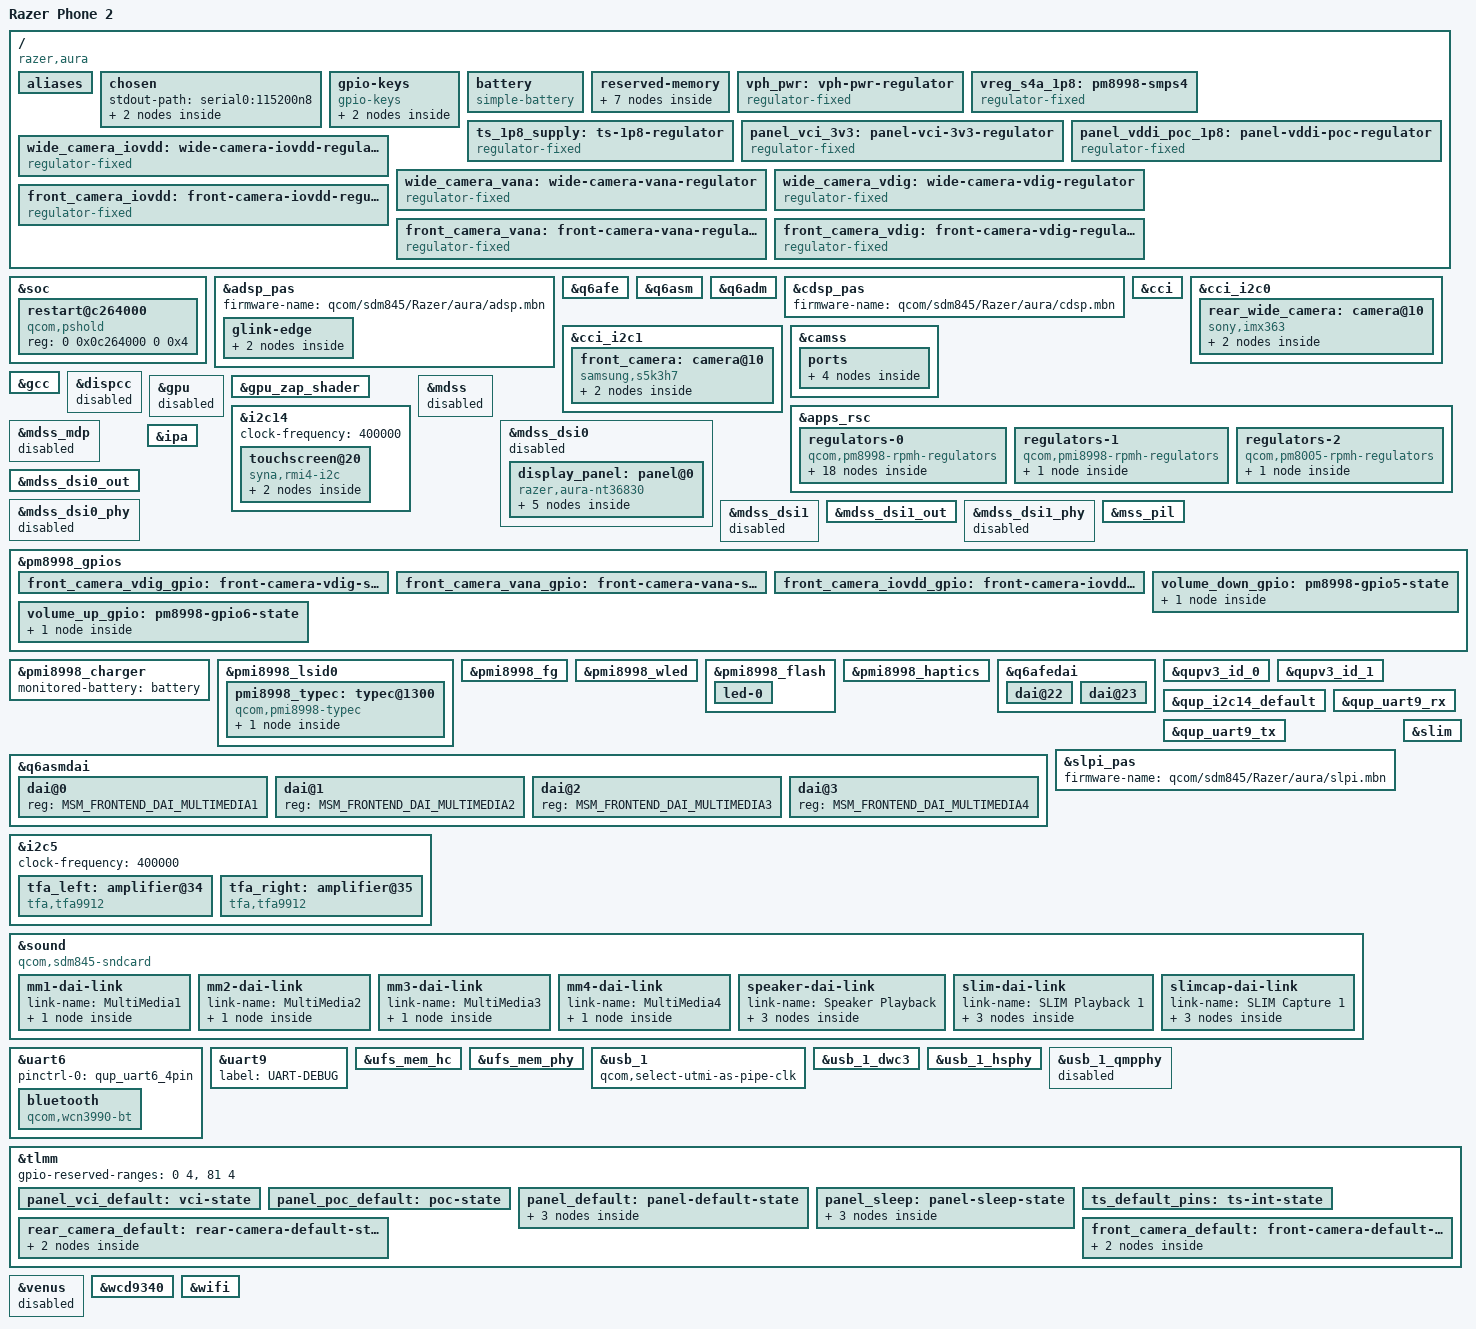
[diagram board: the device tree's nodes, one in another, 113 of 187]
// SPDX-License-Identifier: GPL-2.0
/*
 * SDM845 Razer Phone 2 (aura) device tree source.
 *
 * Copyright (c) 2024 Linux Community
 *
 * Based on sdm845-oneplus-common.dtsi / sdm845-oneplus-fajita.dts
 * and information extracted from Razer Phone 2 Android kernel sources.
 *
 * Hardware:
 *   SoC:     Qualcomm SDM845 (Snapdragon 845)
 *   Display: NovaTeK NT36830 5.72" 1440x2560 120Hz AMOLED (Dual DSI + DSC)
 *   Touch:   Synaptics RMI4 DSX on I2C-14 @ 0x20
 *   WiFi:    Qualcomm WCN3990 (ath10k_snoc)
 *   PMIC:    PM8998 (primary) + PMI8998 (secondary)
 *   USB:     DWC3 (a600000.dwc3) USB 3.1 Type-C
 *   Audio:   WCD9340 (tavil) via Slimbus
 *   Storage: UFS 2.1 (1d84000.ufshc)
 */

/dts-v1/;

#include <dt-bindings/arm/qcom,ids.h>
#include <dt-bindings/gpio/gpio.h>
#include <dt-bindings/input/input.h>
#include <dt-bindings/input/linux-event-codes.h>
#include <dt-bindings/input/qcom,spmi-haptics.h>
#include <dt-bindings/leds/common.h>
#include <dt-bindings/phy/phy-qcom-qusb2.h>
#include <dt-bindings/pinctrl/qcom,pmic-gpio.h>
#include <dt-bindings/regulator/qcom,rpmh-regulator.h>
#include <dt-bindings/sound/qcom,q6afe.h>
#include <dt-bindings/sound/qcom,q6asm.h>
#include <dt-bindings/usb/pd.h>

#include "sdm845.dtsi"
#include "sdm845-wcd9340.dtsi"
#include "pm8998.dtsi"
#include "pmi8998.dtsi"

/delete-node/ &rmtfs_mem;

/ {
	model = "Razer Phone 2";
	compatible = "razer,aura", "qcom,sdm845";
	chassis-type = "handset";

	/*
	 * Match the factory Android boot DTB. Keep this revision aligned while
	 * validating TZ-authenticated MSS firmware loading.
	 */
	qcom,msm-id = <QCOM_ID_SDM845 0x20000>;
	qcom,board-id = <0 0>;

	aliases {
		serial0 = &uart9;
		serial1 = &uart6;
	};

	chosen {
		#address-cells = <2>;
		#size-cells = <2>;
		ranges;

		stdout-path = "serial0:115200n8";

		/*
		 * Keep the bootloader framebuffer alive for the debug-safe display path.
		 * This mirrors the previously successful PMOS-style bring-up direction:
		 * preserve simpledrm first, and defer full NT36830 takeover until the
		 * rest of the boot chain is observable and stable.
		 */
		framebuffer: framebuffer@9d400000 {
			compatible = "simple-framebuffer";
			reg = <0 0x9d400000 0 0x00f00000>;
			width = <1440>;
			height = <2560>;
			stride = <(1440 * 4)>;
			format = "a8r8g8b8";

			/*
			 * Fake panel node for simpledrm DPI calculation and saner probe
			 * ordering, following the conservative SDM845 phone bring-up pattern.
			 * 2026-07-06: this was dropped when the 7.1 DTS was adopted from
			 * codex/linux-7.1-display, which is why 7.1 had no /dev/fb0 or
			 * /dev/dri at all (simpledrm never created a device) even though
			 * the same physical bootloader framebuffer worked fine on 6.16.
			 */
			panel = <&fb_panel>;

			fb_panel: fb-panel {
				width-mm = <71>;
				height-mm = <126>;
			};
		};
	};

	gpio-keys {
		compatible = "gpio-keys";
		label = "Volume keys";
		autorepeat;

		pinctrl-names = "default";
		pinctrl-0 = <&volume_down_gpio &volume_up_gpio>;

		key-vol-down {
			label = "Volume down";
			linux,code = <KEY_VOLUMEDOWN>;
			gpios = <&pm8998_gpios 5 GPIO_ACTIVE_LOW>;
			debounce-interval = <15>;
		};

		key-vol-up {
			label = "Volume up";
			linux,code = <KEY_VOLUMEUP>;
			gpios = <&pm8998_gpios 6 GPIO_ACTIVE_LOW>;
			debounce-interval = <15>;
		};
	};

	battery: battery {
		compatible = "simple-battery";

		charge-full-design-microamp-hours = <4000000>;
		voltage-min-design-microvolt = <3400000>;
		/* Factory battery profile: 4.4 V, 4000 mAh. */
		voltage-max-design-microvolt = <4400000>;
		/*
		 * Keep mainline USB DCP charging conservative.  The factory
		 * downstream tree allows up to 3.9 A, but that policy also
		 * depends on downstream JEITA and step-charging support.
		 */
		constant-charge-current-max-microamp = <2000000>;
	};

	reserved-memory {
		/*
		 * Bootloader-painted splash/continuous-splash framebuffer.
		 * 2026-07-07: this region was never marked no-map, so it stayed
		 * part of generic System RAM (confirmed via /proc/iomem:
		 * 97c00000-aeffffff : System RAM covers it). Newer simpledrm
		 * added a strict devm_request_mem_region() acquire in its probe
		 * path, which then fails with -ENOMEM ("could not acquire memory
		 * region") because normal System RAM is already claimed by the
		 * kernel's own memory management. The older simpledrm on 6.16
		 * tolerated the missing reservation; 7.1 does not. Must exactly
		 * match the /chosen/framebuffer@9d400000 reg below.
		 */
		cont_splash_mem: framebuffer-mem@9d400000 {
			reg = <0 0x9d400000 0 0x00f00000>;
			no-map;
		};

		/*
		 * Razer and OnePlus Android downstream DTBs describe rmtfs as a
		 * dynamically allocated 2 MiB sharedmem-uio region with guard memory.
		 * Follow the proven OnePlus mainline pattern for this contrast test:
		 * keep the old SDM845 rmtfs/modem window reserved below, and expose
		 * the active rmtfs region at the high address used by OnePlus.
		 */
		rmtfs_mem: rmtfs-mem@f5b00000 {
			compatible = "qcom,rmtfs-mem";
			reg = <0 0xf5b00000 0 0x202000>;
			no-map;

			qcom,client-id = <1>;
			qcom,vmid = <QCOM_SCM_VMID_MSS_MSA>;
			qcom,use-guard-pages;
		};

		/*
		 * Match the OnePlus/Samsung SDM845 mainline safety reserve for the old
		 * downstream modem/rmtfs window. This keeps Linux from allocating the
		 * area while rmtfs itself is served from the high active region above.
		 */
		removed_region: removed-region@88f00000 {
			no-map;
			reg = <0 0x88f00000 0 0x1c00000>;
		};

		/*
		 * Ramoops region for persistent kernel crash logs.
		 * Survives warm reboots for post-mortem debugging.
		 */
		ramoops: ramoops@ac300000 {
			compatible = "ramoops";
			reg = <0 0xac300000 0 0x400000>;
			record-size = <0x40000>;
			console-size = <0x40000>;
			ftrace-size = <0x40000>;
			pmsg-size = <0x200000>;
			ecc-size = <16>;
		};

		/*
		 * FIH/Razer downstream reserves these OEM regions. They are not
		 * directly consumed by mainline drivers yet, but they should not
		 * be handed to Linux while validating modem firmware stability.
		 */
		fih_nv_mem: fih-nv@af000000 {
			compatible = "removed-dma-pool";
			no-map;
			reg = <0 0xaf000000 0 0x800000>;
		};

		fih_pstore_mem: fih-pstore@af800000 {
			compatible = "removed-dma-pool";
			no-map;
			reg = <0 0xaf800000 0 0x200000>;
		};

		fih_mem: fih@afa00000 {
			compatible = "removed-dma-pool";
			no-map;
			reg = <0 0xafa00000 0 0x600000>;
		};
	};

	/*
	 * Main battery/bus power rail. On Razer Phone 2, this is supplied
	 * by the 4.2V battery through a protection board.
	 */
	vph_pwr: vph-pwr-regulator {
		compatible = "regulator-fixed";
		regulator-name = "vph_pwr";
		regulator-min-microvolt = <3700000>;
		regulator-max-microvolt = <3700000>;
	};

	/*
	 * PM8998 SMPS4 is always-on and not managed by RPMh.
	 * Model as fixed 1.8V regulator.
	 */
	vreg_s4a_1p8: pm8998-smps4 {
		compatible = "regulator-fixed";
		regulator-name = "vreg_s4a_1p8";

		regulator-min-microvolt = <1800000>;
		regulator-max-microvolt = <1800000>;

		regulator-always-on;
		regulator-boot-on;

		vin-supply = <&vph_pwr>;
	};

	/*
	 * Touchscreen 1.8V I/O supply, controlled via GPIO.
	 * Modeled as fixed regulator since we don't have schematics.
	 */
	ts_1p8_supply: ts-1p8-regulator {
		compatible = "regulator-fixed";
		regulator-name = "ts_1p8_supply";

		regulator-min-microvolt = <1800000>;
		regulator-max-microvolt = <1800000>;

		gpio = <&tlmm 88 GPIO_ACTIVE_HIGH>;
		enable-active-high;
	};

	/*
	 * Display panel VCI 3.3V supply.
	 * Controlled via TLMM GPIO, active high.
	 */
	panel_vci_3v3: panel-vci-3v3-regulator {
		compatible = "regulator-fixed";
		regulator-name = "LCD_VCI_3V";

		regulator-min-microvolt = <3300000>;
		regulator-max-microvolt = <3300000>;

		gpio = <&tlmm 26 GPIO_ACTIVE_HIGH>;
		enable-active-high;
		pinctrl-0 = <&panel_vci_default>;
		pinctrl-names = "default";
		regulator-boot-on;
		regulator-always-on;
	};

	/*
	 * Display panel VDDI / POC 1.8V supply.
	 * Controlled via TLMM GPIO, active high.
	 */
	panel_vddi_poc_1p8: panel-vddi-poc-regulator {
		compatible = "regulator-fixed";
		regulator-name = "VDDI_POC";

		regulator-min-microvolt = <1800000>;
		regulator-max-microvolt = <1800000>;

		gpio = <&tlmm 25 GPIO_ACTIVE_HIGH>;
		enable-active-high;
		pinctrl-0 = <&panel_poc_default>;
		pinctrl-names = "default";
		regulator-boot-on;
		regulator-always-on;
	};

	/* Rear wide-camera I/O rail from the factory RC2 camera topology. */
	wide_camera_iovdd: wide-camera-iovdd-regulator {
		compatible = "regulator-fixed";
		regulator-name = "wide_camera_iovdd";
		regulator-min-microvolt = <1800000>;
		regulator-max-microvolt = <1800000>;
		regulator-enable-ramp-delay = <233>;
		vin-supply = <&vreg_lvs1a_1p8>;
		gpio = <&pm8998_gpios 11 GPIO_ACTIVE_HIGH>;
		enable-active-high;
	};

	wide_camera_vana: wide-camera-vana-regulator {
		compatible = "regulator-fixed";
		regulator-name = "wide_camera_vana";
		regulator-min-microvolt = <3312000>;
		regulator-max-microvolt = <3312000>;
		vin-supply = <&vreg_bob>;
		gpio = <&pm8998_gpios 12 GPIO_ACTIVE_HIGH>;
		enable-active-high;
	};

	wide_camera_vdig: wide-camera-vdig-regulator {
		compatible = "regulator-fixed";
		regulator-name = "wide_camera_vdig";
		regulator-min-microvolt = <1352000>;
		regulator-max-microvolt = <1352000>;
		vin-supply = <&vreg_s3a_1p35>;
		gpio = <&pm8998_gpios 10 GPIO_ACTIVE_HIGH>;
		enable-active-high;
	};

	/* Chicony S5K3H7 front-camera rails from the factory RC2 topology. */
	front_camera_iovdd: front-camera-iovdd-regulator {
		compatible = "regulator-fixed";
		regulator-name = "front_camera_iovdd";
		regulator-min-microvolt = <1800000>;
		regulator-max-microvolt = <1800000>;
		regulator-enable-ramp-delay = <233>;
		vin-supply = <&vreg_lvs1a_1p8>;
		gpio = <&pm8998_gpios 8 GPIO_ACTIVE_HIGH>;
		pinctrl-names = "default";
		pinctrl-0 = <&front_camera_iovdd_gpio>;
		enable-active-high;
	};

	front_camera_vana: front-camera-vana-regulator {
		compatible = "regulator-fixed";
		regulator-name = "front_camera_vana";
		regulator-min-microvolt = <2800000>;
		regulator-max-microvolt = <2800000>;
		gpio = <&pm8998_gpios 7 GPIO_ACTIVE_HIGH>;
		pinctrl-names = "default";
		pinctrl-0 = <&front_camera_vana_gpio>;
		enable-active-high;
	};

	front_camera_vdig: front-camera-vdig-regulator {
		compatible = "regulator-fixed";
		regulator-name = "front_camera_vdig";
		regulator-min-microvolt = <1050000>;
		regulator-max-microvolt = <1050000>;
		gpio = <&pm8998_gpios 4 GPIO_ACTIVE_HIGH>;
		pinctrl-names = "default";
		pinctrl-0 = <&front_camera_vdig_gpio>;
		enable-active-high;
	};
};

/*
 * Razer's downstream SDM845 poweroff path drops PS_HOLD at 0x0c264000
 * after programming PM8998 PON for shutdown. PSCI SYSTEM_OFF returns on
 * this firmware, so expose the register to the mainline msm-poweroff driver.
 */
&soc {
	restart@c264000 {
		compatible = "qcom,pshold";
		reg = <0 0x0c264000 0 0x4>;
	};
};

/*
 * ==========================================================================
 * Subsystem Firmware Paths
 * ==========================================================================
 * Firmware blobs extracted from Razer Phone 2 stock ROM.
 * Place in /usr/lib/firmware/qcom/sdm845/Razer/aura/
 */

&adsp_pas {
	firmware-name = "qcom/sdm845/Razer/aura/adsp.mbn";
	/*
	 * WiFi/MSS controlled test: factory Android keeps ADSP/SLPI/CDSP
	 * available. Keep audio/SLIM users disabled, but allow the remoteproc
	 * domain to boot so modem root_pd can resolve early dependencies.
	 */
	status = "okay";

	/*
	 * Razer's stock ADSP image exposes APR over GLINK, but its service
	 * registry does not publish msm/adsp/audio_pd. Register the audio APR
	 * children as soon as the edge appears instead of waiting forever for a
	 * protection-domain notification that this firmware cannot send.
	 */
	glink-edge {
		apr {
			service@3 {
				/delete-property/ qcom,protection-domain;
			};
		};
	};
};

&q6afe {
	/delete-property/ qcom,protection-domain;
};

&q6asm {
	/delete-property/ qcom,protection-domain;
};

&q6adm {
	/delete-property/ qcom,protection-domain;
};

&cdsp_pas {
	firmware-name = "qcom/sdm845/Razer/aura/cdsp.mbn";
	status = "okay";
};

/*
 * Factory rear-wide topology: Lite-On IMX363, CCI0, CSIPHY0, MCLK0 on
 * GPIO13, reset on GPIO80. Autofocus and OIS are not needed for preview.
 */
&cci {
	status = "okay";
};

&cci_i2c0 {
	status = "okay";

	rear_wide_camera: camera@10 {
		compatible = "sony,imx363";
		reg = <0x10>;
		clocks = <&clock_camcc CAM_CC_MCLK0_CLK>;
		assigned-clocks = <&clock_camcc CAM_CC_MCLK0_CLK>;
		assigned-clock-rates = <24000000>;
		clock-frequency = <24000000>;
		pinctrl-names = "default";
		pinctrl-0 = <&rear_camera_default>;
		reset-gpios = <&tlmm 80 GPIO_ACTIVE_LOW>;
		vif-supply = <&wide_camera_iovdd>;
		vana-supply = <&wide_camera_vana>;
		vdig-supply = <&wide_camera_vdig>;
		orientation = <1>;
		rotation = <90>;

		port {
			rear_imx363_ep: endpoint {
				bus-type = <4>;
				clock-lanes = <1>;
				data-lanes = <1 2 3 4>;
				link-frequencies = /bits/ 64 <636000000 321000000>;
				remote-endpoint = <&camss_csiphy0_ep>;
			};
		};
	};
};

&cci_i2c1 {
	status = "okay";

	front_camera: camera@10 {
		compatible = "samsung,s5k3h7";
		reg = <0x10>;
		clocks = <&clock_camcc CAM_CC_MCLK2_CLK>;
		assigned-clocks = <&clock_camcc CAM_CC_MCLK2_CLK>;
		assigned-clock-rates = <24000000>;
		clock-frequency = <24000000>;
		pinctrl-names = "default";
		pinctrl-0 = <&front_camera_default>;
		reset-gpios = <&tlmm 9 GPIO_ACTIVE_LOW>;
		vdda-supply = <&front_camera_vana>;
		vddd-supply = <&front_camera_vdig>;
		vddio-supply = <&front_camera_iovdd>;
		orientation = <0>;
		rotation = <90>;

		port {
			front_s5k3h7_ep: endpoint {
				bus-type = <4>;
				clock-lanes = <1>;
				data-lanes = <1 2 3 4>;
				link-frequencies = /bits/ 64 <330000000>;
				remote-endpoint = <&camss_csiphy2_ep>;
			};
		};
	};
};

&camss {
	vdda-phy-supply = <&vdda_mipi_dsi0_pll>;
	vdda-pll-supply = <&vdda_mipi_dsi0_1p2>;
	vdda-csi0-supply = <&vdda_mipi_dsi0_pll>;
	vdda-csi1-supply = <&vdda_mipi_dsi0_pll>;
	vdda-csi2-supply = <&vdda_mipi_dsi0_pll>;
	status = "okay";

	ports {
		#address-cells = <1>;
		#size-cells = <0>;

		port@0 {
			reg = <0>;
			camss_csiphy0_ep: endpoint {
				bus-type = <4>;
				clock-lanes = <7>;
				data-lanes = <0 1 2 3>;
				remote-endpoint = <&rear_imx363_ep>;
			};
		};

		port@2 {
			reg = <2>;
			camss_csiphy2_ep: endpoint {
				bus-type = <4>;
				clock-lanes = <7>;
				data-lanes = <0 1 2 3>;
				remote-endpoint = <&front_s5k3h7_ep>;
			};
		};
	};
};

/*
 * ==========================================================================
 * RPMh Regulators (PM8998 + PMI8998)
 * ==========================================================================
 * Voltage values derived from Razer Phone 2 Android kernel device tree.
 * PM8998 provides core rail SMPS and peripheral LDO regulators.
 * PMI8998 provides BOB (Battery-on-Board) bypass regulator.
 */
&apps_rsc {
	regulators-0 {
		compatible = "qcom,pm8998-rpmh-regulators";
		qcom,pmic-id = "a";

		vdd-s1-supply = <&vph_pwr>;
		vdd-s2-supply = <&vph_pwr>;
		vdd-s3-supply = <&vph_pwr>;
		vdd-s4-supply = <&vph_pwr>;
		vdd-s5-supply = <&vph_pwr>;
		vdd-s6-supply = <&vph_pwr>;
		vdd-s7-supply = <&vph_pwr>;
		vdd-s8-supply = <&vph_pwr>;
		vdd-s9-supply = <&vph_pwr>;
		vdd-s10-supply = <&vph_pwr>;
		vdd-s11-supply = <&vph_pwr>;
		vdd-s12-supply = <&vph_pwr>;
		vdd-s13-supply = <&vph_pwr>;
		vdd-l1-l27-supply = <&vreg_s7a_1p025>;
		vdd-l2-l8-l17-supply = <&vreg_s3a_1p35>;
		vdd-l3-l11-supply = <&vreg_s7a_1p025>;
		vdd-l4-l5-supply = <&vreg_s7a_1p025>;
		vdd-l6-supply = <&vph_pwr>;
		vdd-l7-l12-l14-l15-supply = <&vreg_s5a_2p04>;
		vdd-l9-supply = <&vreg_bob>;
		vdd-l10-l23-l25-supply = <&vreg_bob>;
		vdd-l13-l19-l21-supply = <&vreg_bob>;
		vdd-l16-l28-supply = <&vreg_bob>;
		vdd-l18-l22-supply = <&vreg_bob>;
		vdd-l20-l24-supply = <&vreg_bob>;
		vdd-l26-supply = <&vreg_s3a_1p35>;
		vin-lvs-1-2-supply = <&vreg_s4a_1p8>;

		/* SMPS3: CX/MX related, 1.352V */
		vreg_s3a_1p35: smps3 {
			regulator-min-microvolt = <1352000>;
			regulator-max-microvolt = <1352000>;
		};

		/* SMPS5: I/O rail, 2.04V */
		vreg_s5a_2p04: smps5 {
			regulator-min-microvolt = <1904000>;
			regulator-max-microvolt = <2040000>;
		};

		/* SMPS7: Core logic, 1.025V */
		vreg_s7a_1p025: smps7 {
			regulator-min-microvolt = <900000>;
			regulator-max-microvolt = <1028000>;
		};

		/* LDO1: USB SS PHY core + DSI PLL analog, 0.88V (nldo) */
		vdda_usb1_ss_core:
		vdda_mipi_dsi0_pll: ldo1 {
			regulator-min-microvolt = <880000>;
			regulator-max-microvolt = <880000>;
			regulator-initial-mode = <RPMH_REGULATOR_MODE_HPM>;
		};

		/* LDO2: DDR/SRAM, 1.2V (always-on) */
		vreg_l2a_1p2: ldo2 {
			regulator-min-microvolt = <1200000>;
			regulator-max-microvolt = <1200000>;
			regulator-initial-mode = <RPMH_REGULATOR_MODE_HPM>;
			regulator-always-on;
		};

		/* LDO5: WCSS CX/MX supply for WiFi/BT, 0.8V */
		vreg_l5a_0p8: ldo5 {
			regulator-min-microvolt = <800000>;
			regulator-max-microvolt = <800000>;
			regulator-initial-mode = <RPMH_REGULATOR_MODE_HPM>;
		};

		/* LDO7: WiFi/BT XO, UFS core, 1.8V */
		vreg_l7a_1p8: ldo7 {
			regulator-min-microvolt = <1800000>;
			regulator-max-microvolt = <1800000>;
			regulator-initial-mode = <RPMH_REGULATOR_MODE_HPM>;
		};

		/* LDO10: General purpose 1.8V (pldo, range 1.664-3.704V) */
		vreg_l10a_1p8: ldo10 {
			regulator-min-microvolt = <1704000>;
			regulator-max-microvolt = <2928000>;
			regulator-initial-mode = <RPMH_REGULATOR_MODE_HPM>;
		};

		/* LDO12: QUSB2 HS PHY, 1.8V */
		vdda_qusb_hs0_1p8: ldo12 {
			regulator-min-microvolt = <1800000>;
			regulator-max-microvolt = <1800000>;
			regulator-initial-mode = <RPMH_REGULATOR_MODE_HPM>;
		};

		/* LDO14: DSI panel VDDIO, 1.88V (boot-on for splash screen) */
		vreg_l14a_1p88: ldo14 {
			regulator-min-microvolt = <1800000>;
			regulator-max-microvolt = <1800000>;
			regulator-initial-mode = <RPMH_REGULATOR_MODE_HPM>;
			regulator-boot-on;
			regulator-always-on;
		};

		/* LDO17: WiFi/BT RFA, 1.3V */
		vreg_l17a_1p3: ldo17 {
			regulator-min-microvolt = <1304000>;
			regulator-max-microvolt = <1304000>;
			regulator-initial-mode = <RPMH_REGULATOR_MODE_HPM>;
		};

		/* LDO20: UFS VCC, 2.95V */
		vreg_l20a_2p95: ldo20 {
			regulator-min-microvolt = <2704000>;
			regulator-max-microvolt = <2960000>;
			regulator-initial-mode = <RPMH_REGULATOR_MODE_HPM>;
		};

		/* LDO23: WiFi/BT CH1, 3.3V */
		vreg_l23a_3p3: ldo23 {
			regulator-min-microvolt = <3300000>;
			regulator-max-microvolt = <3312000>;
			regulator-initial-mode = <RPMH_REGULATOR_MODE_HPM>;
		};

		/* LDO24: QUSB2 HS PHY DPDM, 3.088V */
		vdda_qusb_hs0_3p1: ldo24 {
			regulator-min-microvolt = <3088000>;
			regulator-max-microvolt = <3088000>;
			regulator-initial-mode = <RPMH_REGULATOR_MODE_HPM>;
		};

		/* LDO25: WiFi/BT CH0, 3.3V */
		vreg_l25a_3p3: ldo25 {
			regulator-min-microvolt = <3300000>;
			regulator-max-microvolt = <3312000>;
			regulator-initial-mode = <RPMH_REGULATOR_MODE_HPM>;
		};

		/* LDO26: DSI PHY PLL, UFS PHY & USB SS PHY, 1.2V */
		vdda_usb1_ss_1p2:
		vdda_mipi_dsi0_1p2: ldo26 {
			regulator-min-microvolt = <1200000>;
			regulator-max-microvolt = <1200000>;
			regulator-initial-mode = <RPMH_REGULATOR_MODE_HPM>;
		};

		/* LDO28: Touch/sensor supply, 3.0V */
		vreg_l28a_3p0: ldo28 {
			regulator-min-microvolt = <2856000>;
			regulator-max-microvolt = <3008000>;
			regulator-initial-mode = <RPMH_REGULATOR_MODE_HPM>;
		};

		/* Factory camera I/O rail: PM8998 LVS1 fed from S4. */
		vreg_lvs1a_1p8: lvs1 {
			regulator-min-microvolt = <1800000>;
			regulator-max-microvolt = <1800000>;
		};
	};

	/* PMI8998 BOB (Battery-on-Board) bypass regulator */
	regulators-1 {
		compatible = "qcom,pmi8998-rpmh-regulators";
		qcom,pmic-id = "b";

		vdd-bob-supply = <&vph_pwr>;

		vreg_bob: bob {
			regulator-min-microvolt = <3312000>;
			regulator-max-microvolt = <3600000>;
			regulator-initial-mode = <RPMH_REGULATOR_MODE_AUTO>;
			regulator-allow-bypass;
		};
	};

	/* PM8005 (tertiary PMIC) SMPS regulators */
	regulators-2 {
		compatible = "qcom,pm8005-rpmh-regulators";
		qcom,pmic-id = "c";

		vdd-s1-supply = <&vph_pwr>;
		vdd-s2-supply = <&vph_pwr>;
		vdd-s3-supply = <&vph_pwr>;
		vdd-s4-supply = <&vph_pwr>;

		/* SMPS3: GFX/GPU supply, 0.6V */
		vreg_s3c_0p6: smps3 {
			regulator-min-microvolt = <600000>;
			regulator-max-microvolt = <600000>;
		};
	};
};

/*
 * ==========================================================================
 * Clock Controller
 * ==========================================================================
 */
&gcc {
	protected-clocks = <GCC_QSPI_CORE_CLK>,
			   <GCC_QSPI_CORE_CLK_SRC>,
			   <GCC_QSPI_CNOC_PERIPH_AHB_CLK>,
			   <GCC_LPASS_Q6_AXI_CLK>,
			   <GCC_LPASS_SWAY_CLK>;
};

/*
 * ==========================================================================
 * Display/GPU clocks
 * ==========================================================================
 *
 * Stage 1 validates Linux 7.1 while preserving the known-good bootloader
 * framebuffer. Keep these clock domains disabled so probing cannot reset the
 * bootloader scanout before the native NT36830 test stage.
 */
&dispcc {
	status = "disabled";
};

&gpu {
	status = "disabled";
};

/*
 * Adreno 630 zap shader: device-signed split image extracted from the
 * phone's Android vendor_a partition (/vendor/firmware/a630_zap.*). The
 * .mdt split format is loaded by the same mdt loader as .mbn. Generic
 * a630_sqe.fw comes from the same partition; a630_gmu.bin from
 * linux-firmware. Same firmware-name pattern as sdm845-oneplus-common.
 */
&gpu_zap_shader {
	firmware-name = "qcom/sdm845/Razer/aura/a630_zap.mdt";
};

/*
 * ==========================================================================
 * Touchscreen (Synaptics RMI4 DSX)
 * ==========================================================================
 * The Razer Phone 2 uses a Synaptics RMI4 touch controller on I2C bus 14
 * (QUP SE 14 @ 0xa98000) at slave address 0x20.
 *
 * GPIO mapping (from Android kernel RC2_common/touch_synaptics_3708.dtsi):
 *   - Interrupt: TLMM GPIO 31 (active low, level)
 *   - Reset:     TLMM GPIO 32
 *   - Power:     TLMM GPIO 44 (1.8V LDO enable)
 *   - Supply:    VDD = LDO28 (3.0V), VIO = ts_1p8_supply
 *
 * Note: GPIO 122 = MAG_INT_N (magnetometer interrupt), NOT touch IRQ.
 */
&i2c14 {
	status = "okay";
	clock-frequency = <400000>;

	touchscreen@20 {
		compatible = "syna,rmi4-i2c";
		reg = <0x20>;
		#address-cells = <1>;
		#size-cells = <0>;
		interrupts-extended = <&tlmm 31 IRQ_TYPE_LEVEL_LOW>;

		pinctrl-names = "default";
		pinctrl-0 = <&ts_default_pins>;

		vdd-supply = <&vreg_l28a_3p0>;
		vio-supply = <&ts_1p8_supply>;

		syna,reset-delay-ms = <200>;
		syna,startup-delay-ms = <200>;

		rmi4-f01@1 {
			reg = <0x01>;
			syna,nosleep-mode = <1>;
		};

		rmi4-f12@12 {
			reg = <0x12>;
			touchscreen-x-mm = <68>;
			touchscreen-y-mm = <120>;
			syna,sensor-type = <1>;
			syna,rezero-wait-ms = <200>;
		};
	};
};

/*
 * ==========================================================================
 * Display Subsystem (MDSS / Dual DSI / NT36830)
 * ==========================================================================
 * The Razer Phone 2 display uses a NovaTeK NT36830 controller driving a
 * 1440x2560 120Hz AMOLED panel via Dual DSI with Display Stream Compression.
 *
 * Dual DSI configuration:
 *   - DSI0: Left half (720x2560)
 *   - DSI1: Right half (720x2560)
 *   - Combined: 1440x2560
 *
 * Native panel power sequence for the later display-driver test:
 *   1. Enable VDDIO (vreg_l14a_1p88 - 1.8V)
 *   2. Enable VCI (panel_vci_3v3 - 3.3V)
 *   3. Enable POC (panel_vddi_poc_1p8 - 1.8V)
 *   4. Release reset GPIO
 *   5. Send DSI initialization commands
 */
&mdss {
	status = "disabled";
};

&mdss_mdp {
	status = "disabled";
};

&mdss_dsi0 {
	status = "disabled";
	/*
	 * 2026-07-07: mainline's own sdm845.dtsi sets no vdda-supply on
	 * EITHER dsi0 or dsi1 -- this property only exists in this board
	 * file, and it was only ever added to mdss_dsi1 below, not here.
	 * The factory board DTS powers both DSI controllers from the same
	 * named 1.2V analog rail symmetrically (dsi_ctrl0/dsi_ctrl1 both
	 * have vdda-1p2-supply = <&pm8998_l26> in sdm845-sde.dtsi). Leaving
	 * DSI0 without this supply left its analog PLL/PHY rail unpowered
	 * by devicetree while DSI1's was properly enabled -- matches the
	 * observed symptom exactly (stripes/signal-integrity issue on DSI0
	 * only, DSI1 clean).
	 */
	vdda-supply = <&vdda_mipi_dsi0_1p2>;

	qcom,dual-dsi-mode;
	qcom,master-dsi;
	qcom,sync-dual-dsi;

	/*
	 * NT36830 panel node on DSI0 (primary interface).
	 * The panel driver will configure both DSI0 and DSI1 via
	 * the dual-DSI mechanism.
	 *
	 * For dual-DSI: The panel node is defined ONLY on DSI0.
	 * port@0 links to DSI0, port@1 links to DSI1.
	 * The panel driver uses of_graph_get_remote_node(dev, 1, -1)
	 * to find the secondary DSI host.
	 */
	display_panel: panel@0 {
		compatible = "razer,aura-nt36830", "novatek,nt36830";
		reg = <0>;
		backlight = <&pmi8998_wled>;

		/* Power supplies */
		vddio-supply = <&vreg_l14a_1p88>;
		vci-supply = <&panel_vci_3v3>;
		poc-supply = <&panel_vddi_poc_1p8>;

		/* Control GPIOs */
		reset-gpios = <&tlmm 6 GPIO_ACTIVE_LOW>;
		te-gpios = <&tlmm 10 GPIO_ACTIVE_HIGH>;
		/*
		 * panel-mode-gpio (GPIO 52) selects dual DSI mode.
		 * Confirmed from Android DTBO entry-05 qcom,panel-mode-gpio=52.
		 * Currently unused by mainline NT36830 driver.
		 */

		/* Pinctrl states */
		pinctrl-0 = <&panel_default>;
		pinctrl-1 = <&panel_sleep>;
		pinctrl-names = "default", "sleep";

		/*
		 * Dual-DSI port connections.
		 * port@0: primary DSI (DSI0) - left half 720x2560
		 * port@1: secondary DSI (DSI1) - right half 720x2560
		 */
		ports {
			#address-cells = <1>;
			#size-cells = <0>;

			port@0 {
				reg = <0>;
				panel_in_dsi0: endpoint {
					remote-endpoint = <&mdss_dsi0_out>;
				};
			};

			port@1 {
				reg = <1>;
				panel_in_dsi1: endpoint {
					remote-endpoint = <&mdss_dsi1_out>;
				};
			};
		};
	};
};

&mdss_dsi0_out {
	remote-endpoint = <&panel_in_dsi0>;
	data-lanes = <0 1 2 3>;
};

&mdss_dsi0_phy {
	status = "disabled";
	/*
	 * 2026-07-07: factory panel DTS
	 * (qcom,mdss_dsi_nt36830_wqhd_dualdsi_extclk_cmd) hand-tunes these two
	 * D-PHY clock-lane timing values for this exact panel+board instead of
	 * using the SoC-generic computed defaults. Requires kernel-patches/
	 * 0002-drm-msm-dsi-honor-factory-clk-post-pre-override.patch --
	 * mainline's dsi_phy_10nm.c has no DT plumbing for these two factory
	 * properties otherwise and would silently ignore them.
	 */
	qcom,mdss-dsi-t-clk-post = <0x0b>;
	qcom,mdss-dsi-t-clk-pre = <0x21>;
};

/*
 * DSI1: Secondary DSI for dual-DSI panel configuration.
 * No panel node here - the panel is only defined on DSI0.
 * DSI1 is linked via port@1 on the panel node.
 */
&mdss_dsi1 {
	status = "disabled";
	vdda-supply = <&vdda_mipi_dsi0_1p2>;

	qcom,dual-dsi-mode;

	/* DSI1 is slave, so use DSI0 clocks */
	assigned-clock-parents = <&mdss_dsi0_phy 0>,
				 <&mdss_dsi0_phy 1>;
};

&mdss_dsi1_out {
	remote-endpoint = <&panel_in_dsi1>;
	data-lanes = <0 1 2 3>;
};

&mdss_dsi1_phy {
	status = "disabled";
	/*
	 * LK ground truth (register capture 2026-07-07): the bootloader
	 * programs t_clk_post/pre = 0x0b/0x21 on BOTH DSI controllers, not
	 * just DSI0. Same mechanism as the dsi0_phy override above
	 * (kernel-patches/0002).
	 */
	qcom,mdss-dsi-t-clk-post = <0x0b>;
	qcom,mdss-dsi-t-clk-pre = <0x21>;
};

/*
 * ==========================================================================
 * IPA (Internet Protocol Accelerator)
 * ==========================================================================
 */
&ipa {
	qcom,gsi-loader = "self";
	memory-region = <&ipa_fw_mem>;
	firmware-name = "qcom/sdm845/Razer/aura/ipa_fws.mbn";
	/*
	 * WiFi/MSS controlled test: IPA disabled did not prevent the MSS fatal,
	 * and ADSP/SLPI/CDSP alone did not create WLFW. Restore IPA with the
	 * factory remoteproc set to test whether modem root_pd expects the full
	 * modem data path present, rather than treating IPA as the trigger.
	 */
	status = "okay";
};

/*
 * ==========================================================================
 * Modem / WiFi Subsystem
 * ==========================================================================
 */
&mss_pil {
	status = "okay";
	firmware-name = "qcom/sdm845/Razer/aura/mba.mbn",
			"qcom/sdm845/Razer/aura/modem.mbn";
	qcom,fih-nv-memory-region = <&fih_nv_mem>;
};

/*
 * ==========================================================================
 * PMIC GPIO Configuration
 * ==========================================================================
 */
&pm8998_gpios {
	front_camera_vdig_gpio: front-camera-vdig-state {
		pins = "gpio4";
		function = "normal";
		output-low;
		qcom,drive-strength = <PMIC_GPIO_STRENGTH_LOW>;
		power-source = <0>;
	};

	front_camera_vana_gpio: front-camera-vana-state {
		pins = "gpio7";
		function = "normal";
		output-low;
		qcom,drive-strength = <PMIC_GPIO_STRENGTH_LOW>;
		power-source = <0>;
	};

	front_camera_iovdd_gpio: front-camera-iovdd-state {
		pins = "gpio8";
		function = "normal";
		output-low;
		qcom,drive-strength = <PMIC_GPIO_STRENGTH_LOW>;
		power-source = <0>;
	};

	volume_down_gpio: pm8998-gpio5-state {
		pinconf {
			pins = "gpio5";
			function = "normal";
			input-enable;
			bias-pull-up;
			qcom,drive-strength = <0>;
		};
	};

	volume_up_gpio: pm8998-gpio6-state {
		pinconf {
			pins = "gpio6";
			function = "normal";
			input-enable;
			bias-pull-up;
			qcom,drive-strength = <0>;
		};
	};
};

/*
 * ==========================================================================
 * PMI8998 Charger and Fuel Gauge
 * ==========================================================================
 * Keep these enabled in the base device tree and build their drivers into
 * the kernel. Charging must not depend on reaching userspace or loading a
 * module from rootfs when the battery is already low.
 */
&pmi8998_charger {
	status = "okay";
	monitored-battery = <&battery>;
};

/*
 * PMI8998 integrates the Type-C state machine in the SMB2 USBIN peripheral
 * and provides a separate SPMI PD PHY at 0x1700.  Keep the first PD bring-up
 * sink-only: the external 5 V source regulator used by factory Android is not
 * modelled yet, and charging does not require source/host mode.
 */
&pmi8998_lsid0 {
	pmi8998_typec: typec@1300 {
		compatible = "qcom,pmi8998-typec";
		reg = <0x1300>, <0x1700>;

		interrupts = <0x2 0x13 0x7 IRQ_TYPE_EDGE_BOTH>,
			     <0x2 0x17 0x0 IRQ_TYPE_EDGE_RISING>,
			     <0x2 0x17 0x1 IRQ_TYPE_EDGE_RISING>,
			     <0x2 0x17 0x2 IRQ_TYPE_EDGE_RISING>,
			     <0x2 0x17 0x3 IRQ_TYPE_EDGE_RISING>,
			     <0x2 0x17 0x4 IRQ_TYPE_EDGE_RISING>,
			     <0x2 0x17 0x5 IRQ_TYPE_EDGE_RISING>,
			     <0x2 0x17 0x6 IRQ_TYPE_EDGE_RISING>;
		interrupt-names = "type-c-change",
				  "sig-tx",
				  "sig-rx",
				  "msg-tx",
				  "msg-rx",
				  "msg-tx-failed",
				  "msg-tx-discarded",
				  "msg-rx-discarded";

		vdd-pdphy-supply = <&vdda_qusb_hs0_3p1>;
		power-supply = <&pmi8998_charger>;
		status = "okay";

		connector {
			compatible = "usb-c-connector";
			power-role = "sink";
			data-role = "device";
			try-power-role = "sink";

			op-sink-microwatt = <13500000>;
			sink-pdos = <PDO_FIXED(5000, 1500, PDO_FIXED_USB_COMM)
				     PDO_FIXED(9000, 1500, PDO_FIXED_USB_COMM)>;
		};
	};
};

&pmi8998_fg {
	status = "okay";
	power-supplies = <&pmi8998_charger>;
	monitored-battery = <&battery>;
};

/*
 * ==========================================================================
 * PMI8998 WLED (White LED / Backlight)
 * ==========================================================================
 */
&pmi8998_wled {
	/* Razer/FIH rc2 factory values translated to the mainline binding. */
	qcom,enabled-strings = <0 1 2 3>;
	qcom,current-limit-microamp = <20000>;
	qcom,current-boost-limit = <970>;
	qcom,ovp-millivolt = <29600>;
	qcom,switching-freq = <1600>;
	qcom,cabc;
	max-brightness = <4095>;
	default-brightness = <2048>;
	status = "okay";
};

/*
 * ==========================================================================
 * PMI8998 Flash LED
 * ==========================================================================
 */
&pmi8998_flash {
	status = "okay";

	led-0 {
		function = LED_FUNCTION_FLASH;
		color = <LED_COLOR_ID_WHITE>;
		led-sources = <1>;
		led-max-microamp = <500000>;
		flash-max-microamp = <1500000>;
		flash-max-timeout-us = <1280000>;
	};
};

/*
 * ==========================================================================
 * PMI8998 LRA Haptics
 * ==========================================================================
 * Razer's downstream PMI8998 node uses direct play, a 1.3 V maximum, the
 * 800 mA current limit and a 6667 us sample period. Mainline's buffer mode
 * exposes the same actuator through the standard EV_FF/FF_RUMBLE interface.
 */
&pmi8998_haptics {
	status = "okay";
	qcom,actuator-type = <HAP_TYPE_LRA>;
	qcom,wave-shape = <HAP_WAVE_SINE>;
	qcom,play-mode = <HAP_PLAY_DIRECT>;
	qcom,vmax-mv = <1300>;
	qcom,current-limit-milliamp = <800>;
	qcom,wave-play-rate-us = <6667>;
	qcom,lra-auto-res-mode = <HAP_AUTO_RES_NONE>;
	qcom,brake-pattern = <0x3 0x3 0x2 0x1>;
};

/*
 * ==========================================================================
 * Audio Subsystem (QQ6/ASM/AFE DAIs)
 * ==========================================================================
 */
&q6afedai {
	dai@22 {
		reg = <QUATERNARY_MI2S_RX>;
		qcom,sd-lines = <0 1>;
	};

	dai@23 {
		reg = <QUATERNARY_MI2S_TX>;
		qcom,sd-lines = <0>;
	};
};

&q6asmdai {
	dai@0 {
		reg = <MSM_FRONTEND_DAI_MULTIMEDIA1>;
	};

	dai@1 {
		reg = <MSM_FRONTEND_DAI_MULTIMEDIA2>;
	};

	dai@2 {
		reg = <MSM_FRONTEND_DAI_MULTIMEDIA3>;
	};

	dai@3 {
		reg = <MSM_FRONTEND_DAI_MULTIMEDIA4>;
	};
};

/*
 * ==========================================================================
 * QUP (Qualcomm Unified Peripheral) Bus Controllers
 * ==========================================================================
 */
&qupv3_id_0 {
	status = "okay";
};

&qupv3_id_1 {
	status = "okay";
};

/*
 * The SMR7 RC2 audio DTS identifies two NXP TFA9912 smart amplifiers on
 * QUPv3 SE5. Their factory container is installed as tfa98xx.cnt.
 */
&i2c5 {
	clock-frequency = <400000>;
	status = "okay";

	tfa_left: amplifier@34 {
		compatible = "tfa,tfa9912";
		reg = <0x34>;
		#sound-dai-cells = <0>;
		sound-name-prefix = "Left";
	};

	tfa_right: amplifier@35 {
		compatible = "tfa,tfa9912";
		reg = <0x35>;
		#sound-dai-cells = <0>;
		sound-name-prefix = "Right";
	};
};

&qup_i2c14_default {
	drive-strength = <2>;
	bias-disable;
};

&qup_uart9_rx {
	drive-strength = <2>;
	bias-pull-up;
};

&qup_uart9_tx {
	drive-strength = <2>;
	bias-disable;
};

/*
 * ==========================================================================
 * SLPI (Sensor Low Power Island)
 * ==========================================================================
 */
&slpi_pas {
	firmware-name = "qcom/sdm845/Razer/aura/slpi.mbn";
	/*
	 * WiFi/MSS controlled test: Razer's Android DT keeps SLPI enabled and
	 * factory firmware contains slpi root/sensor service-registry entries.
	 */
	status = "okay";
};

/*
 * ==========================================================================
 * SLIMbus Audio Transport
 * ==========================================================================
 */
&slim {
	status = "okay";
};

/*
 * ==========================================================================
 * Sound Card
 * ==========================================================================
 */
&sound {
	compatible = "qcom,sdm845-sndcard";
	model = "Razer Phone 2";
	pinctrl-0 = <&quat_mi2s_active &quat_mi2s_sd0_active &quat_mi2s_sd1_active>;
	pinctrl-names = "default";
	status = "okay";

	audio-routing = "RX_BIAS", "MCLK",
			"AMIC1", "MIC BIAS3",
			"AMIC2", "MIC BIAS2",
			"AMIC3", "MIC BIAS4",
			"AMIC4", "MIC BIAS1",
			"AMIC5", "MIC BIAS3";

	mm1-dai-link {
		link-name = "MultiMedia1";
		cpu {
			sound-dai = <&q6asmdai MSM_FRONTEND_DAI_MULTIMEDIA1>;
		};
	};

	mm2-dai-link {
		link-name = "MultiMedia2";
		cpu {
			sound-dai = <&q6asmdai MSM_FRONTEND_DAI_MULTIMEDIA2>;
		};
	};

	mm3-dai-link {
		link-name = "MultiMedia3";
		cpu {
			sound-dai = <&q6asmdai MSM_FRONTEND_DAI_MULTIMEDIA3>;
		};
	};

	mm4-dai-link {
		link-name = "MultiMedia4";
		cpu {
			sound-dai = <&q6asmdai MSM_FRONTEND_DAI_MULTIMEDIA4>;
		};
	};

	speaker-dai-link {
		link-name = "Speaker Playback";
		cpu {
			sound-dai = <&q6afedai QUATERNARY_MI2S_RX>;
		};

		platform {
			sound-dai = <&q6routing>;
		};

		codec {
			sound-dai = <&tfa_left>, <&tfa_right>;
		};
	};

	slim-dai-link {
		link-name = "SLIM Playback 1";
		cpu {
			sound-dai = <&q6afedai SLIMBUS_0_RX>;
		};

		platform {
			sound-dai = <&q6routing>;
		};

		codec {
			sound-dai = <&wcd9340 0>;
		};
	};

	slimcap-dai-link {
		link-name = "SLIM Capture 1";
		cpu {
			sound-dai = <&q6afedai SLIMBUS_0_TX>;
		};

		platform {
			sound-dai = <&q6routing>;
		};

		codec {
			sound-dai = <&wcd9340 1>;
		};
	};
};

/*
 * ==========================================================================
 * Bluetooth (WCN3990, integrated with WiFi)
 * ==========================================================================
 * Uses UART6 with 4-pin flow control for HCI transport.
 */
&uart6 {
	/*
	 * Enable WCN3990 Bluetooth for the BT-firmware contrast build. This keeps
	 * the test narrower than the earlier full-peripheral build: only the BT
	 * HCI transport and QCA firmware path are added while SLIM/audio stay off.
	 */
	status = "okay";

	pinctrl-0 = <&qup_uart6_4pin>;

	bluetooth {
		compatible = "qcom,wcn3990-bt";

		firmware-name = "Razer/aura/crnv21.bin";

		vddio-supply = <&vreg_s4a_1p8>;
		vddxo-supply = <&vreg_l7a_1p8>;
		vddrf-supply = <&vreg_l17a_1p3>;
		vddch0-supply = <&vreg_l25a_3p3>;
		max-speed = <3200000>;

		/*
		 * Razer factory BT MAC 44:5E:CD:B1:1B:60 (read on Android from
		 * /sys/module/fih_mfd/parameters/bt_mac). Mainline has no fih_mfd
		 * provider, so without this the controller registers as
		 * HCI_UNCONFIGURED (no valid BD_ADDR) and HCIDEVUP returns
		 * -EOPNOTSUPP (errno 95). Property bytes are little-endian, i.e.
		 * the MAC reversed: 44:5E:CD:B1:1B:60 -> [60 1B B1 CD 5E 44].
		 */
		local-bd-address = [60 1B B1 CD 5E 44];
	};
};

/*
 * ==========================================================================
 * Debug UART (Serial Console)
 * ==========================================================================
 */
&uart9 {
	label = "UART-DEBUG";
	status = "okay";
};

/*
 * ==========================================================================
 * UFS Storage Controller
 * ==========================================================================
 * UFS 2.1 with hardware reset via TLMM GPIO 150.
 */
&ufs_mem_hc {
	status = "okay";

	reset-gpios = <&tlmm 150 GPIO_ACTIVE_LOW>;

	vcc-supply = <&vreg_l20a_2p95>;
	vcc-max-microamp = <600000>;
};

&ufs_mem_phy {
	status = "okay";

	vdda-phy-supply = <&vreg_l7a_1p8>;
	vdda-pll-supply = <&vdda_mipi_dsi0_1p2>;
};

/*
 * ==========================================================================
 * USB 3.1 Controller (DWC3)
 * ==========================================================================
 * The Razer Phone 2 has USB 3.1 Gen 1 via Type-C connector.
 *
 * For early mainline bring-up, prefer a conservative USB2 peripheral path.
 * This keeps the board description aligned with the debug-safe DTB that has
 * been producing artifacts under WSL, and keeps Windows-visible source and
 * built output in sync.
 */
&usb_1 {
	status = "okay";
	qcom,select-utmi-as-pipe-clk;
};

&usb_1_dwc3 {
	dr_mode = "peripheral";
	maximum-speed = "high-speed";
	phys = <&usb_1_hsphy>;
	phy-names = "usb2-phy";
};

&usb_1_hsphy {
	status = "okay";

	vdd-supply = <&vdda_usb1_ss_core>;
	vdda-pll-supply = <&vdda_qusb_hs0_1p8>;
	vdda-phy-dpdm-supply = <&vdda_qusb_hs0_3p1>;

	qcom,imp-res-offset-value = <8>;
	qcom,hstx-trim-value = <QUSB2_V2_HSTX_TRIM_21_6_MA>;
	qcom,preemphasis-level = <QUSB2_V2_PREEMPHASIS_5_PERCENT>;
	qcom,preemphasis-width = <QUSB2_V2_PREEMPHASIS_WIDTH_HALF_BIT>;
};

&usb_1_qmpphy {
	status = "disabled";
};

/*
 * ==========================================================================
 * TLMM (Top Level Mode Mux) Pin Controller
 * ==========================================================================
 * GPIO reserved ranges correspond to firmware-owned GPIO blocks.
 */
&tlmm {
	gpio-reserved-ranges = <0 4>, <81 4>;

	/* Panel VCI 3.3V GPIO control */
	panel_vci_default: vci-state {
		pins = "gpio26";
		function = "gpio";
		drive-strength = <8>;
		bias-disable;
	};

	/* Panel POC 1.8V GPIO control */
	panel_poc_default: poc-state {
		pins = "gpio25";
		function = "gpio";
		drive-strength = <8>;
		bias-disable;
	};

	/* Panel default state: reset + TE + ESD */
	panel_default: panel-default-state {
		esd-pins {
			pins = "gpio30";
			function = "gpio";
			drive-strength = <2>;
			bias-pull-down;
		};

		reset-pins {
			pins = "gpio6";
			function = "gpio";
			drive-strength = <8>;
			bias-disable;
		};

		te-pins {
			pins = "gpio10";
			function = "mdp_vsync";
			drive-strength = <2>;
			bias-disable;
		};
	};

	/* Panel sleep state: low power */
	panel_sleep: panel-sleep-state {
		esd-pins {
			pins = "gpio30";
			function = "gpio";
			drive-strength = <2>;
			bias-pull-down;
		};

		reset-pins {
			pins = "gpio6";
			function = "gpio";
			drive-strength = <2>;
			bias-pull-down;
		};

		te-pins {
			pins = "gpio10";
			function = "mdp_vsync";
			drive-strength = <2>;
			bias-disable;
		};
	};

	/* Touchscreen interrupt + reset pins */
	/* GPIO 31 = TOUCH_INT, GPIO 32 = TOUCH_RST (from RC2_common/touch_synaptics_3708.dtsi) */
	ts_default_pins: ts-int-state {
		pins = "gpio31", "gpio32";
		function = "gpio";
		drive-strength = <16>;
		bias-pull-up;
	};

	rear_camera_default: rear-camera-default-state {
		mclk-pins {
			pins = "gpio13";
			function = "cam_mclk";
			drive-strength = <2>;
			bias-disable;
		};

		reset-pins {
			pins = "gpio80";
			function = "gpio";
			drive-strength = <2>;
			bias-disable;
		};
	};

	front_camera_default: front-camera-default-state {
		mclk-pins {
			pins = "gpio15";
			function = "cam_mclk";
			drive-strength = <2>;
			bias-disable;
		};

		reset-pins {
			pins = "gpio9";
			function = "gpio";
			drive-strength = <2>;
			bias-disable;
		};
	};
};

/*
 * ==========================================================================
 * Venus Video Decoder/Encoder
 * ==========================================================================
 */
&venus {
	firmware-name = "qcom/sdm845/Razer/aura/venus.mbn";
	status = "disabled";
};

/*
 * ==========================================================================
 * Audio Codec (WCD9340 / tavil)
 * ==========================================================================
 */
&wcd9340 {
	status = "okay";

	pinctrl-0 = <&wcd_intr_default>;
	pinctrl-names = "default";
	reset-gpios = <&tlmm 64 GPIO_ACTIVE_HIGH>;
	vdd-buck-supply = <&vreg_s4a_1p8>;
	vdd-buck-sido-supply = <&vreg_s4a_1p8>;
	vdd-tx-supply = <&vreg_s4a_1p8>;
	vdd-rx-supply = <&vreg_s4a_1p8>;
	vdd-io-supply = <&vreg_s4a_1p8>;

	qcom,micbias1-microvolt = <2700000>;
	qcom,micbias2-microvolt = <2700000>;
	qcom,micbias3-microvolt = <2700000>;
	qcom,micbias4-microvolt = <2700000>;
};

/*
 * ==========================================================================
 * WiFi (Qualcomm WCN3990 - ath10k_snoc)
 * ==========================================================================
 * The WCN3990 is an integrated WiFi/BT chip connected via SNOC (System NoC).
 * Uses the ath10k_snoc driver in mainline Linux.
 *
 * Required firmware files in /usr/lib/firmware/ath10k/WCN3990/hw1.0/:
 *   - board.bin (or board-2.bin with calibration data)
 *   - firmware-5.bin
 */
&wifi {
	status = "okay";

	vdd-0.8-cx-mx-supply = <&vreg_l5a_0p8>;
	vdd-1.8-xo-supply = <&vreg_l7a_1p8>;
	vdd-1.3-rfa-supply = <&vreg_l17a_1p3>;
	vdd-3.3-ch0-supply = <&vreg_l25a_3p3>;
	vdd-3.3-ch1-supply = <&vreg_l23a_3p3>;

	qcom,calibration-variant = "razer_aura";
	/*
	 * Razer's WLAN.HL.2.0.c10-00085 firmware exposes WLFW successfully,
	 * but rejects MSA_INFO with QMI_ERR_INCOMPATIBLE_STATE when mainline
	 * ath10k sends HOST_CAP first. Skipping HOST_CAP lets MSA setup,
	 * firmware boot, phy0, wlan0, and scanning complete.
	 */
	qcom,snoc-host-cap-skip-quirk;
};
